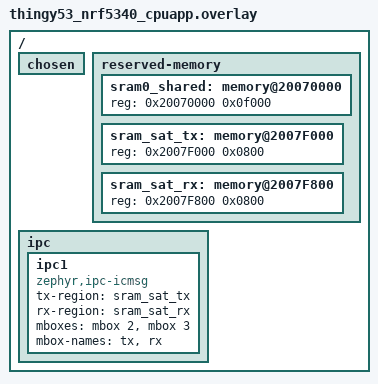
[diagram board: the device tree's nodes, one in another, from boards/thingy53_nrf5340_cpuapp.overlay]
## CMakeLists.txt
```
# Copyright (c) 2024 HubbleNetwork
# SPDX-License-Identifier: Apache-2.0

cmake_minimum_required(VERSION 3.13.1)
find_package(Zephyr REQUIRED HINTS $ENV{ZEPHYR_BASE})

project(app LANGUAGES C)

if (CONFIG_APP_USE_PASS_PREDICTION)
  if("$ENV{HUBBLE_API_TOKEN}" STREQUAL "")
    message(FATAL_ERROR "HUBBLE_API_TOKEN environment variable must be set")
  endif()

  add_custom_command(
    OUTPUT ${CMAKE_CURRENT_SOURCE_DIR}/src/sat_params.c
    COMMAND ${Python3_EXECUTABLE} ${ZEPHYR_HUBBLENETWORK_SDK_MODULE_DIR}/tools/orbital_params_fetch.py
    ${CMAKE_CURRENT_SOURCE_DIR}/src/
    DEPENDS ${ZEPHYR_HUBBLENETWORK_SDK_MODULE_DIR}/tools/orbital_params_fetch.py
    COMMENT "Generate EPP files needed for pass prediction"
  )
  add_custom_target(gen_epp DEPENDS ${CMAKE_CURRENT_SOURCE_DIR}/src/sat_params.c)

  # main.c #includes the generated sat_params.c, so the app target must not be
  # compiled until generation has run.
  add_dependencies(app gen_epp)
endif()

target_sources(app PRIVATE src/ble.c)
target_sources(app PRIVATE src/main.c)
target_sources(app PRIVATE src/nvs.c)
target_sources(app PRIVATE src/sat_board.c)
target_sources(app PRIVATE src/sensor.c)
target_sources(app PRIVATE src/shell.c)
target_sources(app PRIVATE src/button.c)

target_sources_ifdef(CONFIG_APP_BLINK_LED app PRIVATE src/led.c)

target_include_directories(app PRIVATE ${CMAKE_CURRENT_SOURCE_DIR}/common)

include(ExternalProject)
```

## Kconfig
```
# Copyright (c) 2026 HubbleNetwork
# SPDX-License-Identifier: Apache-2.0
#
# This file is the application Kconfig entry point. All application Kconfig
# options can be defined here or included via other application Kconfig files.
# You can browse these options using the west targets menuconfig (terminal) or
# guiconfig (GUI).

menu "Zephyr"
source "Kconfig.zephyr"
endmenu

menu "Hubble Network options"

config HUBBLE_DEVICE_KEY
    string "Cryptography key in base64"
    default ""
    help
	Hubble device's cryptographic key

config HUBBLE_RETRANSMISSION_FREQUENCY
    int "Internval between packet"
    default 4
    help
	Period between packets transmissions in a given window.

config HUBBLE_SAMPLE_ADV_FREQUENCY
    int "Frequency to generate new advertisment in seconds"
    default 28800 # 8 hours
    help
        The maximum time to generate a new advertisement packet.
	It must be less than 24h.

config APP_USE_PASS_PREDICTION
    bool "Use pass prediction instead of timestamps"
    help
        Use Hubble Pass prediction algorithm to determine when
	to transmit to satellite.

config APP_BLINK_LED
    bool "Blink LED during satellite transmission"
    select GPIO
    help
        Blink the LED on top of the device to inform when
	it is transmitting to satellite.

if APP_BLINK_LED

choice
	prompt "LED Color for Satellite transmission"
	default APP_LED_RED
	help
	    Select the led color for during satellite transmission.

config APP_LED_RED
	bool "Use red led"

config APP_LED_GREEN
	bool "Use green led"

config APP_LED_BLUE
	bool "Use blue led"

endchoice

endif # APP_BLINK_LED

endmenu

module = APP
module-str = APP
source "subsys/logging/Kconfig.template.log_config"
```

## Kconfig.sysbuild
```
source "share/sysbuild/Kconfig"

config CPUNET_BOARD
string
	default "thingy53/nrf5340/cpunet" if $(BOARD) = "thingy53"
```

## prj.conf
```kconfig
CONFIG_PRINTK=y

CONFIG_IPC_SERVICE=y
CONFIG_IPC_SERVICE_BACKEND_ICMSG=y
CONFIG_MBOX=y

CONFIG_ASSERT=y
CONFIG_HUBBLE_BLE_NETWORK=y
CONFIG_HUBBLE_SAT_NETWORK=y
# CONFIG_LOG=y

# DEBUG

CONFIG_BT=y
CONFIG_BT_BUF_ACL_TX_COUNT=7
CONFIG_BT_SMP=y
CONFIG_BT_PERIPHERAL=y
CONFIG_SYSTEM_WORKQUEUE_STACK_SIZE=2048

CONFIG_BT_DEVICE_NAME="Hubble Network"

CONFIG_BASE64=y


# Enable MCUmgr and dependencies.
# CONFIG_NET_BUF=y
# CONFIG_ZCBOR=y
# CONFIG_CRC=y
# CONFIG_STREAM_FLASH=y
# CONFIG_FLASH_MAP=y

# Some command handlers require a large stack.
CONFIG_SYSTEM_WORKQUEUE_STACK_SIZE=2304
CONFIG_MAIN_STACK_SIZE=2048

# Enable flash operations.
CONFIG_FLASH=y

# Enable most core commands.
CONFIG_NVS=y
CONFIG_FLASH_PAGE_LAYOUT=y


# Shell - Minimize options
CONFIG_SHELL=y
CONFIG_SHELL_PROMPT_UART="HubbleNetwork:~$ "
CONFIG_DEVICE_SHELL=n
CONFIG_DEVICE_SHELL_INIT_CMD=n
CONFIG_DATE_SHELL=n
CONFIG_DEVMEM_SHELL=n
CONFIG_APP_VERSION_SHELL=n
CONFIG_KERNEL_SHELL=n
CONFIG_SHELL_STATS=n
CONFIG_SHELL_CMDS=n
CONFIG_SHELL_CMDS_RESIZE=n

# Sensor
CONFIG_SENSOR=y
CONFIG_SENSOR_INFO=y

CONFIG_BME680=y

# Banner
CONFIG_BOOT_BANNER_STRING="Hubble Network Thingy53"

# GPIO for button
CONFIG_GPIO=y


# Pass prediction
CONFIG_APP_USE_PASS_PREDICTION=y
```

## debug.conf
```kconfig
# Copyright (c) 2024 HubbleNetwork
# SPDX-License-Identifier: Apache-2.0
#
# compiler
CONFIG_DEBUG_OPTIMIZATIONS=y

# logging
CONFIG_LOG=y
CONFIG_APP_LOG_LEVEL_DBG=y
```

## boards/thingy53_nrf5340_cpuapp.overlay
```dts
/*
 * Copyright (c) 2022 Nordic Semiconductor ASA
 *
 * SPDX-License-Identifier: Apache-2.0
 */

/delete-node/ &sram0_shared;

/ {
	chosen {
		/delete-property/ zephyr,ipc_shm;
	};

	reserved-memory {
		#address-cells = <1>;
		#size-cells = <1>;

		sram0_shared: memory@20070000 {
			/* Last 60 kB of sram0 */
			reg = <0x20070000 0x0f000>;
		};

		sram_sat_tx: memory@2007F000 {
			reg = <0x2007F000 0x0800>;
		};

		sram_sat_rx: memory@2007F800 {
			reg = <0x2007F800 0x0800>;
		};
	};

	ipc {
		ipc1: ipc1 {
			compatible = "zephyr,ipc-icmsg";
			tx-region = <&sram_sat_tx>;
			rx-region = <&sram_sat_rx>;
			mboxes = <&mbox 2>, <&mbox 3>;
			mbox-names = "tx", "rx";
			status = "okay";
		};
	};
};
```

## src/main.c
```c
/*
 * Copyright (c) 2026 HubbleNetwork
 *
 * SPDX-License-Identifier: Apache-2.0
 */
#include <zephyr/kernel.h>
#include <zephyr/bluetooth/bluetooth.h>
#include <zephyr/logging/log.h>
#include <zephyr/sys/util.h>
#include <zephyr/sys/base64.h>
#include <zephyr/sys/byteorder.h>
#include <zephyr/ipc/ipc_service.h>

#include <nrf53_cpunet_mgmt.h>

#include <hubble/hubble.h>

#include <math.h>
#include <stdio.h>
#include <stdlib.h>

#include "app.h"
#include "ble.h"
#include "nvs.h"
#include "sat.h"
#include "shell.h"

/* sat ipc packet */
#include "sat_ipc.h"

#define IPC_TIMEOUT_S 3U

LOG_MODULE_REGISTER(main);

K_SEM_DEFINE(timer_sem, 0, 1);
K_SEM_DEFINE(init_sem, 0, 1);
K_SEM_DEFINE(key_sem, 0, 1);
K_SEM_DEFINE(bound_sem, 0, 1);
K_SEM_DEFINE(sat_sem, 0, 1);

K_MUTEX_DEFINE(radio_mutex);

#ifdef CONFIG_APP_USE_PASS_PREDICTION
#include "sat_params.c"
#endif

static uint8_t _hubble_key[CONFIG_HUBBLE_KEY_SIZE];
static struct ipc_ept ep;
uint64_t utc_time;

/* Set a mark in a shared memory so the cpunet can
 * check which stack (BLE or Satellite) should be used
 * when boot.
 *
 * @_val: 1 for Bluetooth Stack
 *        0 for Satellite Stack
 */
#define _CPUNET_STACK_MARK(_val)                                               \
	do {                                                                   \
		*HUBBLE_SAT_MARK = _val;                                       \
		__DSB();                                                       \
		__ISB();                                                       \
	} while (0)

static void _ep_recv(const void *data, size_t len, void *priv)
{
	const struct sat_ipc_base *pkt = (const struct sat_ipc_base *)data;

	LOG_DBG("Received IPC data (%d)", len);

	if (pkt->cmd == SAT_CMD_OK) {
		k_sem_give(&sat_sem);
	}
}

int ipc_send(const uint8_t *data, size_t len)
{
	int ret = ipc_service_send(&ep, data, len);

	if (ret < 0) {
		return ret;
	}

	return k_sem_take(&sat_sem, K_SECONDS(IPC_TIMEOUT_S));
}

static void _ep_bound(void *priv)
{
	LOG_DBG("ipc bound");

	k_sem_give(&bound_sem);
}

static struct ipc_ept_cfg ep_cfg = {
	.name = "sat_ipc",
	.cb =
		{
			.bound = _ep_bound,
			.received = _ep_recv,
		},
};

const struct device *sat_ipc;

static int _sat_enable(void)
{
	int err;
	struct sat_ipc_base pkt = {
		.cmd = SAT_CMD_INIT,
	};

	LOG_INF("Run network core");

	_CPUNET_STACK_MARK(0);

	nrf53_cpunet_enable(true);

	sat_ipc = DEVICE_DT_GET(DT_NODELABEL(ipc1));

	err = ipc_service_open_instance(sat_ipc);
	if ((err < 0) && (err != -EALREADY)) {
		LOG_ERR("ipc_service_open_instance() failure");
		return err;
	}

	err = ipc_service_register_endpoint(sat_ipc, &ep, &ep_cfg);
	if (err < 0) {
		LOG_ERR("ipc_service_register_endpoint() failure");
		return err;
	}

	k_sem_take(&bound_sem, K_FOREVER);

	return ipc_send((const uint8_t *)&pkt, sizeof(pkt));
}

static int _sat_disable(void)
{
	int err;

	err = ipc_service_deregister_endpoint(&ep);
	if (err) {
		LOG_ERR("Deregistering HCI endpoint failed with: %d", err);
		return err;
	}

	err = ipc_service_close_instance(sat_ipc);
	if (err != 0) {
		LOG_ERR("Closing ipc service  failed with %d\n", err);
		return err;
	}

	nrf53_cpunet_enable(false);

	return 0;
}

int crypto_key_set(const char *key, size_t len)
{
	int ret;
	size_t olen;

	if (len != (ceil((double)CONFIG_HUBBLE_KEY_SIZE / 3) * 4)) {
		return -EINVAL;
	}

	ret = base64_decode(_hubble_key, sizeof(_hubble_key), &olen, key, len);
	if (ret == 0) {
		(void)hubble_nvs_write(HUBBLE_KEY_ID, _hubble_key,
				       sizeof(_hubble_key));
		k_sem_give(&key_sem);
	}

	return ret;
}

static int _key_get(void)
{
	if (hubble_nvs_read(HUBBLE_KEY_ID, _hubble_key, sizeof(_hubble_key)) ==
	    sizeof(_hubble_key)) {
		return 0;
	}

	return -ENOENT;
}

bool crypto_key_is_set(void)
{
	char _k[CONFIG_HUBBLE_KEY_SIZE] = {0};

	return memcmp(_hubble_key, _k, CONFIG_HUBBLE_KEY_SIZE) != 0;
}

int main(void)
{
	int err;

	if (_key_get() == 0) {
		k_sem_give(&key_sem);
	} else if (strlen(CONFIG_HUBBLE_DEVICE_KEY) != 0) {
		err = crypto_key_set(CONFIG_HUBBLE_DEVICE_KEY,
				     strlen(CONFIG_HUBBLE_DEVICE_KEY));
		if (err != 0) {
			LOG_ERR("Invalid key provided!");
		}
	}

	_CPUNET_STACK_MARK(1);

	err = bt_enable(NULL);
	if (err != 0) {
		LOG_ERR("Bluetooth init failed (err %d)", err);
		return err;
	}

	err = ble_init();
	if (err != 0) {
		goto end;
	}

	/* We sit here waiting to have UTC and KEY */
	k_sem_take(&init_sem, K_FOREVER);
	k_sem_take(&key_sem, K_FOREVER);

	/* Initialize utc time. */
	err = hubble_init(utc_time, _hubble_key);
	if (err != 0) {
		LOG_ERR("Failed to initialize Hubble BLE Network");
		return err;
	}

#ifdef CONFIG_APP_USE_PASS_PREDICTION
	err = hubble_sat_satellites_set(sats, ARRAY_SIZE(sats));
	if (err != 0) {
		LOG_ERR("Failed to set Hubble Sats");
		return err;
	}
#endif

	while (true) {
		(void)sat_schedule_next_transmission();
		/**
		 * Here we are assuming that we are going to transmit to
		 * satellite at least once a day, otherwise we will not be able
		 * to synchronize with the BLE network.
		 */
		ble_enable(false);

		/* After that we will be transmitting to satellite */
		k_sem_take(&timer_sem, K_FOREVER);

		ble_disable(false);

		k_mutex_lock(&radio_mutex, K_FOREVER);
		err = _sat_enable();
		if (err < 0) {
			LOG_ERR("Failed to enable satellite IPC: %d", err);
			goto sat_cleanup;
		}

		err = sat_transmit();
		if (err < 0) {
			LOG_WRN("Failed to transmit packet");
		}

sat_cleanup:
		_sat_disable();
		k_mutex_unlock(&radio_mutex);
		_CPUNET_STACK_MARK(1);
	}
end:
	bt_disable();

	return err;
}
```

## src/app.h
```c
/*
 * Copyright (c) 2026 HubbleNetwork
 *
 * SPDX-License-Identifier: Apache-2.0
 */

/**
 * @file app.h
 * @brief Application-level interface for SAT transmission and sensor access.
 *
 * Provides functions to configure and trigger SAT transmissions, send raw IPC
 * messages, and read sensor data from the board.
 */

#ifndef APP_H
#define APP_H

#include <inttypes.h>
#include <stdlib.h>

#include <zephyr/drivers/sensor.h>


extern struct k_mutex radio_mutex;

/**
 * @brief Payload type for a SAT transmission.
 *
 * Selects the kind of data embedded in the SAT packet. Sensor-backed values
 * map directly to the corresponding Zephyr @c sensor_channel so the correct
 * channel is sampled automatically.
 */
enum sat_payload_type {
	CUSTOM, /**< Arbitrary caller-supplied bytes. */
	GAUGE_VOLTAGE = SENSOR_CHAN_GAUGE_VOLTAGE, /**< Battery gauge voltage. */
	TEMP = SENSOR_CHAN_AMBIENT_TEMP,           /**< Ambient temperature. */
	PRESSURE = SENSOR_CHAN_PRESS,              /**< Atmospheric pressure. */
	HUMIDITY = SENSOR_CHAN_HUMIDITY,           /**< Relative humidity. */
	INVALID, /**< Sentinel / error value. */
};

/**
 * @brief Send raw bytes over the inter-processor IPC channel.
 *
 * @param data Pointer to the data buffer to send.
 * @param len  Number of bytes to send.
 * @return 0 on success, negative errno on failure.
 */
int ipc_send(const uint8_t *data, size_t len);

/**
 * @brief Read a sensor value from the board.
 *
 * @param[out] data    Pointer to a @c sensor_value struct that receives the
 *                     measurement.
 * @param      channel Zephyr sensor channel to sample.
 * @return 0 on success, negative errno on failure.
 */
int sensor_data_get(struct sensor_value *data, enum sensor_channel channel);


/**
 * @brief Set the cryptographic key used for SAT payload encryption.
 *
 * @param key Pointer to the key material.
 * @param len Length of the key in bytes.
 * @return 0 on success, negative errno on failure.
 */
int crypto_key_set(const char *key, size_t len);

/**
 * @brief Check whether a cryptographic key has been configured.
 *
 * @return true if a key has been set, false otherwise.
 */
bool crypto_key_is_set(void);

/**
 * @brief Set the device's geographic location for satellite pass prediction.
 *
 * The coordinates are used to compute upcoming satellite passes. This is a
 * no-op unless @c CONFIG_APP_USE_PASS_PREDICTION is enabled.
 *
 * @param lat Latitude in decimal degrees (WGS-84), positive north.
 * @param lon Longitude in decimal degrees (WGS-84), positive east.
 */
void device_location_set(double lat, double lon);

#endif /* APP_H */
```

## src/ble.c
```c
/*
 * Copyright (c) 2026 HubbleNetwork
 *
 * SPDX-License-Identifier: Apache-2.0
 */
#include <zephyr/sys/util.h>
#include <zephyr/sys/byteorder.h>
#include <zephyr/sys/reboot.h>

#include <zephyr/logging/log.h>

#include <zephyr/bluetooth/bluetooth.h>
#include <zephyr/bluetooth/hci.h>
#include <zephyr/bluetooth/hci_vs.h>
#include <zephyr/bluetooth/conn.h>
#include <zephyr/bluetooth/uuid.h>
#include <zephyr/bluetooth/gatt.h>

#include <hubble/hubble.h>
#include <hubble/ble.h>

#include "app.h"
#include "ble.h"
#include "sat.h"

LOG_MODULE_REGISTER(ble);

#define HUBBLE_BLE_UUID_CONNECTABLE 0xFCA7
#define HUBBLE_BLE_BUFFER_LEN       31

#define SPBLE_PKT_CMD               0x02
#define SPBLE_CMD_SETUTC            0x02
#define SPBLE_CMD_SETEPHEMERIS      0x07
#define SPBLE_CMD_SETLOCATION       0x09

#define SVC_UUID                                                               \
	BT_UUID_128_ENCODE(0xef2dc9a1, 0x40be, 0x44b6, 0x9dda, 0x8a00fcd61dc0)
#define CHR_UUID                                                               \
	BT_UUID_128_ENCODE(0xef2dc9a1, 0x40be, 0x44b6, 0x9dda, 0x8a00fcd61dc1)

static bool ble_off_by_user;

static const struct bt_uuid_128 svc_uuid = BT_UUID_INIT_128(SVC_UUID);
static const struct bt_uuid_128 chr_uuid = BT_UUID_INIT_128(CHR_UUID);

static const struct bt_data sd[] = {
	BT_DATA(BT_DATA_NAME_COMPLETE, CONFIG_BT_DEVICE_NAME,
		sizeof(CONFIG_BT_DEVICE_NAME) - 1),
};

static struct bt_data app_ad[] = {
	BT_DATA_BYTES(BT_DATA_UUID16_ALL,
		      BT_UUID_16_ENCODE(HUBBLE_BLE_UUID_CONNECTABLE)),
	BT_DATA_BYTES(BT_DATA_SVC_DATA16,
		      BT_UUID_16_ENCODE(HUBBLE_BLE_UUID_CONNECTABLE)),
};
static uint8_t app_ad_buffer[HUBBLE_BLE_BUFFER_LEN];

extern struct k_sem init_sem;
extern uint64_t utc_time;

int ble_init(void);

static void _ble_work_handler(struct k_work *work)
{
	ble_adv_stop();

	ble_adv_start();
}

K_WORK_DEFINE(_ble_work, _ble_work_handler);

static void _timer_ble_cb(struct k_timer *timer)
{
	k_work_submit(&_ble_work);
}

K_TIMER_DEFINE(ble_timer, _timer_ble_cb, NULL);

static void _adv_provisioning_work_handler(struct k_work *work)
{
	(void)ble_init();
}

K_WORK_DEFINE(_provisioning_work, _adv_provisioning_work_handler);

int ble_adv_start(void)
{
	int err;
	size_t out_len;

	k_timer_start(&ble_timer, K_SECONDS(CONFIG_HUBBLE_SAMPLE_ADV_FREQUENCY),
		      K_NO_WAIT);

	out_len = ARRAY_SIZE(app_ad_buffer);
	err = hubble_ble_advertise_get(NULL, 0, app_ad_buffer, &out_len);
	if (err != 0) {
		return err;
	}

	app_ad[0] = (struct bt_data)BT_DATA_BYTES(
		BT_DATA_UUID16_ALL, BT_UUID_16_ENCODE(HUBBLE_BLE_UUID));
	app_ad[1].data_len = out_len;
	app_ad[1].type = BT_DATA_SVC_DATA16;
	app_ad[1].data = app_ad_buffer;

	return bt_le_adv_start(
		BT_LE_ADV_PARAM(BT_LE_ADV_OPT_USE_NRPA, BT_GAP_ADV_SLOW_INT_MIN,
				BT_GAP_ADV_SLOW_INT_MAX, NULL),
		app_ad, ARRAY_SIZE(app_ad), NULL, 0);
}

void ble_adv_stop(void)
{
	bt_le_adv_stop();
	k_timer_stop(&ble_timer);
}

static void _connected_cb(struct bt_conn *conn, uint8_t err)
{
	k_timer_stop(&ble_timer);
}

static void _disconnected_cb(struct bt_conn *conn, uint8_t reason)
{
	if (utc_time != 0) {
		k_sem_give(&init_sem);
	} else {
		k_work_submit(&_provisioning_work);
	}
}

BT_CONN_CB_DEFINE(conn_callbacks) = {
	.connected = _connected_cb,
	.disconnected = _disconnected_cb,
};

int ble_init(void)
{
	return bt_le_adv_start(
		BT_LE_ADV_PARAM(BT_LE_ADV_OPT_USE_NRPA | BT_LE_ADV_OPT_CONN,
				BT_GAP_ADV_FAST_INT_MIN_2,
				BT_GAP_ADV_FAST_INT_MAX_2, NULL),
		app_ad, 2, sd, ARRAY_SIZE(sd));
}

static ssize_t _chr_write_cb(struct bt_conn *conn,
			     const struct bt_gatt_attr *attr, const void *data,
			     uint16_t len, uint16_t offset, uint8_t flags)
{
	uint8_t *req = (uint8_t *)data;

	if (flags & BT_GATT_WRITE_FLAG_PREPARE) {
		return 0;
	}

	if (req[0] == SPBLE_PKT_CMD) {
		uint8_t cmd = req[1];

		switch (cmd) {
		case SPBLE_CMD_SETUTC:
			if (len != 10) {
				return BT_GATT_ERR(
					BT_ATT_ERR_INVALID_ATTRIBUTE_LEN);
			} else {
				memcpy(&utc_time, req + 2, sizeof(utc_time));
				hubble_time_set(utc_time);
				utc_time = utc_time - k_uptime_get();
			}
			break;
		case SPBLE_CMD_SETEPHEMERIS:
#ifndef CONFIG_APP_USE_PASS_PREDICTION
			if (len > 2 + sizeof(uint32_t)) {
				uint32_t count = 0;
				size_t entry_size =
					sizeof(uint32_t) + sizeof(uint16_t);
				uint8_t *p = (req + 2) + sizeof(uint32_t);
				size_t available = len - 2 - sizeof(uint32_t);

				memcpy(&count, (req + 2), sizeof(count));

				for (uint32_t i = 0; i < count; i++) {
					if (available < entry_size) {
						break;
					}

					int resp = sat_pass_add(
						*(uint32_t *)p,
						*(uint16_t *)(p +
							      sizeof(uint32_t)));
					if (resp != 0) {
						break;
					}

					p += entry_size;
					available -= entry_size;
				}
			}
#endif /* CONFIG_APP_USE_PASS_PREDICTION */
			break;
		case SPBLE_CMD_SETLOCATION:
#ifdef CONFIG_APP_USE_PASS_PREDICTION
			if (len != 2 + 2 * sizeof(double)) {
				return BT_GATT_ERR(
					BT_ATT_ERR_INVALID_ATTRIBUTE_LEN);
			} else {
				double lat, lon;
				memcpy(&lat, (req + 2), sizeof(double));
				memcpy(&lon, (req + 2) + sizeof(double),
				       sizeof(double));

				device_location_set(lat, lon);
			}
#endif /* CONFIG_APP_USE_PASS_PREDICTION */
			break;
		default:
			break;
		}
	}

	return len;
}

void ble_enable(bool user_requested)
{
	int err;

	k_mutex_lock(&radio_mutex, K_FOREVER);

	if (!user_requested && ble_off_by_user) {
		goto end;
	}

	if (user_requested) {
		ble_off_by_user = false;
	}

	err = bt_enable(NULL);
	if (err != 0 && err != -EALREADY) {
		LOG_ERR("Bluetooth init failed (err %d)", err);
		goto end;
	}

	/* Time is not synced */
	if (utc_time == 0) {
		err = ble_init();
		if (err < 0) {
			LOG_ERR("Failed to advertise time sync: %d", err);
		}
	} else {
		err = ble_adv_start();
		if (err < 0) {
			LOG_ERR("Failed to get the advertisement data: %d", err);
		}
	}

end:
	k_mutex_unlock(&radio_mutex);
}

void ble_disable(bool user_requested)
{
	k_mutex_lock(&radio_mutex, K_FOREVER);

	if (user_requested) {
		ble_off_by_user = true;
	}

	/* Stop the timer and disable BLE */
	ble_adv_stop();
	bt_disable();

	k_mutex_unlock(&radio_mutex);
}

/* Check for BT_GATT_PERM_WRITE_LESC permissions */
BT_GATT_SERVICE_DEFINE(
	vnd_svc, BT_GATT_PRIMARY_SERVICE(&svc_uuid),
	BT_GATT_CHARACTERISTIC(&chr_uuid.uuid,
			       BT_GATT_CHRC_WRITE | BT_GATT_CHRC_NOTIFY |
				       BT_GATT_CHRC_WRITE_WITHOUT_RESP |
				       BT_GATT_CHRC_EXT_PROP,
			       BT_GATT_PERM_WRITE | BT_GATT_PERM_PREPARE_WRITE,
			       NULL, _chr_write_cb, NULL), );
```

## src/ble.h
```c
/*
 * Copyright (c) 2025 HubbleNetwork
 *
 * SPDX-License-Identifier: Apache-2.0
 */

/**
 * @file ble.h
 * @brief Bluetooth LE advertising interface.
 *
 * Provides functions to initialise the BLE stack, control advertising, and
 * query timing information used to synchronise SAT transmissions with BLE
 * advertisement slots.
 */

#ifndef BLE_H
#define BLE_H

#include <zephyr/bluetooth/uuid.h>

/**
 * @brief Initialise the Bluetooth LE subsystem.
 *
 * Registers GATT services, sets up the advertising data, and prepares the
 * controller for use. Must be called once before any other BLE function.
 *
 * @return 0 on success, negative errno on failure.
 */
int ble_init(void);

/**
 * @brief Start Bluetooth LE advertising.
 *
 * Begins broadcasting advertisement packets. @ref ble_init must have been
 * called successfully before invoking this function.
 *
 * @return 0 on success, negative errno on failure.
 */
int ble_adv_start(void);

/**
 * @brief Stop Bluetooth LE advertising.
 *
 * Halts advertisement broadcasting. Safe to call even if advertising is
 * already stopped.
 */
void ble_adv_stop(void);

void ble_enable(bool user_requested);

void ble_disable(bool user_requested);

#endif /* BLE_H */
```

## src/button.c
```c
/*
 * Copyright (c) 2026 HubbleNetwork
 *
 * SPDX-License-Identifier: Apache-2.0
 */

#include <inttypes.h>
#include <zephyr/bluetooth/bluetooth.h>
#include <zephyr/device.h>
#include <zephyr/drivers/gpio.h>
#include <zephyr/kernel.h>

#include "ble.h"

#define SW0_NODE DT_ALIAS(sw0)
#if !DT_NODE_HAS_STATUS_OKAY(SW0_NODE)
#error "Unsupported board: sw0 devicetree alias is not defined"
#endif

static const struct gpio_dt_spec _button =
	GPIO_DT_SPEC_GET_OR(SW0_NODE, gpios, {0});
static struct gpio_callback _button_cb_data;
static struct k_work _button_work;

static void _button_pressed_worker(struct k_work *work)
{
	if (!bt_is_ready()) {
		ble_enable(true);
	} else {
		ble_disable(true);
	}
}

static void _button_pressed(const struct device *dev, struct gpio_callback *cb,
			    uint32_t pins)
{
	/* We are in ISR so let's delegate the task to a work queue. */
	k_work_submit(&_button_work);
}

int _button_init(void)
{
	int ret = 0;

	if (!gpio_is_ready_dt(&_button)) {
		return -1;
	}

	ret = gpio_pin_configure_dt(&_button, GPIO_INPUT);
	if (ret != 0) {
		return ret;
	}

	ret = gpio_pin_interrupt_configure_dt(&_button, GPIO_INT_EDGE_TO_ACTIVE);
	if (ret != 0) {
		return ret;
	}

	gpio_init_callback(&_button_cb_data, _button_pressed, BIT(_button.pin));
	gpio_add_callback(_button.port, &_button_cb_data);

	k_work_init(&_button_work, _button_pressed_worker);

	return ret;
}

SYS_INIT(_button_init, APPLICATION, CONFIG_APPLICATION_INIT_PRIORITY);
```

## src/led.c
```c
/*
 * Copyright (c) 2026 HubbleNetwork
 *
 * SPDX-License-Identifier: Apache-2.0
 */

#include <zephyr/kernel.h>
#include <zephyr/drivers/gpio.h>

#define LED_INTERVAL_S   1

#if defined(CONFIG_APP_LED_GREEN)
#define LED_NODE DT_ALIAS(led1)
#elif defined(CONFIG_APP_LED_BLUE)
#define LED_NODE DT_ALIAS(led2)
#else
#define LED_NODE DT_ALIAS(led0)
#endif

static const struct gpio_dt_spec led = GPIO_DT_SPEC_GET(LED_NODE, gpios);

static void led_blink_cb(struct k_timer *timer)
{
	(void)gpio_pin_toggle_dt(&led);
}

static void led_stop_cb(struct k_timer *timer)
{
	(void)gpio_pin_configure_dt(&led, GPIO_OUTPUT_INACTIVE);
}

K_TIMER_DEFINE(led_timer, led_blink_cb, led_stop_cb);

int led_blink_start(void)
{
	int ret;

	if (!gpio_is_ready_dt(&led)) {
		return -EAGAIN;
	}

	ret = gpio_pin_configure_dt(&led, GPIO_OUTPUT_ACTIVE);
	if (ret < 0) {
		return ret;
	}

	k_timer_start(&led_timer, K_SECONDS(LED_INTERVAL_S), K_SECONDS(LED_INTERVAL_S));

	return 0;
}

void led_blink_stop(void)
{
	k_timer_stop(&led_timer);
}
```

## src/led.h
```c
/*
 * Copyright (c) 2026 HubbleNetwork
 *
 * SPDX-License-Identifier: Apache-2.0
 */

#ifndef LED_H
#define LED_H

#ifdef CONFIG_APP_BLINK_LED

/**
 * @brief Start blinking the LED
 *
 * Start blinking the LED. The LED selection depends on Kconfig: led1 for
 * CONFIG_APP_LED_GREEN, led2 for CONFIG_APP_LED_BLUE, or led0 otherwise.
 *
 * @retval 0 on success.
 * @retval -EAGAIN if the device is not ready.
 * @retval negative errno on GPIO configuration failure.
 */
int led_blink_start(void);

/**
 * @brief Stop blinking the LED and turn it off.
 *
 * Stops blinking the LED.
 */
void led_blink_stop(void);

#else

static inline int led_blink_start(void)
{
	return 0;
}

static inline void led_blink_stop(void)
{
}

#endif	/* CONFIG_APP_BLINK_LED */

#endif 	/* LED_H  */
```

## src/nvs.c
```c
/*
 * Copyright (c) 2025 HubbleNetwork
 *
 * SPDX-License-Identifier: Apache-2.0
 */

#include <zephyr/drivers/flash.h>
#include <zephyr/storage/flash_map.h>
#include <zephyr/kvss/nvs.h>

#include "nvs.h"


#define NVS_PARTITION        storage_partition
#define NVS_PARTITION_DEVICE PARTITION_DEVICE(NVS_PARTITION)
#define NVS_PARTITION_OFFSET PARTITION_OFFSET(NVS_PARTITION)
#define NVS_PARTITION_SIZE   PARTITION_SIZE(NVS_PARTITION)

#define KEY_ID               1

static struct nvs_fs fs;

int _nvs_init(void)
{
	int err;
	struct flash_pages_info info;

	fs.flash_device = NVS_PARTITION_DEVICE;
	if (!device_is_ready(fs.flash_device)) {
		return -1;
	}

	fs.offset = NVS_PARTITION_OFFSET;
	err = flash_get_page_info_by_offs(fs.flash_device, fs.offset, &info);
	if (err != 0) {
		return -1;
	}

	fs.sector_size = info.size;
	fs.sector_count = NVS_PARTITION_SIZE / fs.sector_size;

	err = nvs_mount(&fs);
	if (err != 0) {
		;
		return -1;
	}

	return 0;
}

int hubble_nvs_read(enum hubble_nvs_id id, uint8_t *data, size_t len)
{
	return nvs_read(&fs, id, data, len);
}

int hubble_nvs_write(enum hubble_nvs_id id, const uint8_t *data, size_t len)
{
	(void)nvs_delete(&fs, id);
	return nvs_write(&fs, id, data, len);
}

/* Just using a priority lower than FLASH_INIT_PRIORITY */
SYS_INIT(_nvs_init, APPLICATION, CONFIG_APPLICATION_INIT_PRIORITY);
```

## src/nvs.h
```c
/*
 * Copyright (c) 2025 HubbleNetwork
 *
 * SPDX-License-Identifier: Apache-2.0
 */

/**
 * @file nvs.h
 * @brief Non-volatile storage (NVS) interface for Hubble persistent data.
 *
 * Provides typed read/write access to NVS entries identified by
 * @ref hubble_nvs_id values.
 */

#ifndef NVS_H
#define NVS_H

#include <inttypes.h>

/**
 * @brief Identifiers for Hubble NVS entries.
 */
enum hubble_nvs_id {
	HUBBLE_KEY_ID, /**< Hubble device key. */
};

/**
 * @brief Read data from non-volatile storage (NVS).
 *
 * This function reads data associated with a specific ID from NVS into
 * the provided buffer.
 *
 * @param id   The identifier for the data to be read.
 * @param data Pointer to the buffer where the read data will be stored.
 *             The buffer must be pre-allocated by the caller.
 * @param len  The length of the data to be read, in bytes.
 *             This ensures that the function does not read beyond the
 *             allocated buffer size.
 *
 * @return 0 on success, or a negative value on error.
 *         Possible errors include:
 *         - Invalid ID
 *         - Insufficient buffer size
 *         - Read failure
 */
int hubble_nvs_read(enum hubble_nvs_id id, uint8_t *data, size_t len);

/**
 * @brief Write data to non-volatile storage (NVS).
 *
 * This function writes data to NVS, associating it with a specific ID.
 *
 * @param id   The identifier for the data to be written.
 * @param data Pointer to the buffer containing the data to be written.
 * @param len  The length of the data to be written, in bytes.
 *
 * @return 0 on success, or a negative value on error.
 *         Possible errors include:
 *         - Invalid ID
 *         - Write failure
 *         - Insufficient storage space
 */
int hubble_nvs_write(enum hubble_nvs_id id, const uint8_t *data, size_t len);

#endif /* NVS_H */
```

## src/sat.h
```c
/*
 * Copyright (c) 2026 HubbleNetwork
 *
 * SPDX-License-Identifier: Apache-2.0
 */

/**
 * @file sat.h
 * @brief SAT transmission control interface.
 *
 * Provides functions to configure and drive SAT transmissions: scheduling
 * the next window, tuning RF power and retransmission cadence, setting the
 * payload, and triggering the actual over-the-air burst.
 *
 * Typical call sequence:
 *   1. sat_pass_add() — populate the transmission schedule
 *      from satellite pass data received over BLE.
 *   2. sat_payload_set()             — choose what data to embed in each packet.
 *   3. sat_schedule_next_transmission() — arm the kernel timer for the next window.
 *   4. sat_transmit()                — called from the timer callback to send.
 */

#ifndef SAT_H
#define SAT_H

/**
 * @brief Arm the kernel timer for the next scheduled transmission window.
 *
 * Walks the pre-loaded timestamp table (populated via
 * sat_pass_add()) to find the earliest future satellite pass,
 * then starts a one-shot timer that fires when that window opens.
 *
 * @return 0 on success, -1 when no future window is available.
 */
int sat_schedule_next_transmission(void);

/**
 * @brief Set the SAT retransmission interval.
 *
 * Within a single transmission window the packet is sent repeatedly at this
 * cadence until the window closes.
 *
 * @param retransmission_s Interval between retransmissions, in seconds.
 * @return 0 on success, negative errno on failure.
 */
int sat_retransmission_set(uint8_t retransmission_s);

/**
 * @brief Set the SAT transmit power.
 *
 * @param power Transmit power level in dBm.
 * @return 0 on success, negative errno on failure.
 */
int sat_power_set(int8_t power);

/**
 * @brief Set the payload for the next SAT transmission.
 *
 * For sensor-backed types (TEMP, PRESSURE, HUMIDITY, GAUGE_VOLTAGE) @p data
 * may be NULL and @p len zero — the driver is sampled automatically at
 * transmit time. For CUSTOM, @p data and @p len must describe the raw bytes
 * to embed.
 *
 * @param type Payload type; see @ref sat_payload_type.
 * @param data Pointer to payload bytes, or NULL for sensor-backed types.
 * @param len  Length of @p data in bytes, or 0 for sensor-backed types.
 * @return 0 on success, negative errno on failure.
 */
int sat_payload_set(enum sat_payload_type type, const uint8_t *data, size_t len);

/**
 * @brief Register a satellite pass window with the scheduler.
 *
 * Each call appends one entry to the internal timestamp table.  The table
 * holds up to 300 entries; calls beyond that return -ENOSPC.  Entries are
 * consumed in order by sat_schedule_next_transmission().
 *
 * @param timestamp UTC epoch second at which the pass window opens.
 * @param duration  Length of the pass window in seconds.
 * @return 0 on success, -ENOSPC when the table is full.
 */
int sat_pass_add(uint32_t timestamp, uint16_t duration);

/**
 * @brief Trigger a SAT transmission with the currently configured payload.
 *
 * Builds a Hubble SAT packet from the active payload, then retransmits it
 * repeatedly (at the configured interval) for the duration of the current
 * pass window.  Blocks until the window closes.
 *
 * @return 0 on success, negative errno on failure.
 */
int sat_transmit(void);

/**
 * @brief Query whether a SAT transmission is currently in progress.
 *
 * @return true while sat_transmit() is executing, false otherwise.
 */
bool sat_is_transmitting(void);

/**
 * @brief Get the next scheduled transmission window.
 *
 * Only available when pass prediction (CONFIG_APP_USE_PASS_PREDICTION) is
 * enabled. Returns the start time of the pass most recently armed by
 * sat_schedule_next_transmission().
 *
 * @param timestamps Buffer filled with upcoming pass start times, as Unix
 *                   time in seconds.
 * @param len        Number of entries @p timestamps can hold.
 * @return Number of timestamps written to @p timestamps (0 or more), or -1
 *         when no window is scheduled.
 */
int sat_next_transmission_get(uint32_t *timestamps, uint16_t len);

#endif
```

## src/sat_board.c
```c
/*
 * Copyright (c) 2026 Hubble Network, Inc.
 *
 * SPDX-License-Identifier: Apache-2.0
 */

#include <errno.h>
#include <stddef.h>

#include <zephyr/logging/log.h>
#include <zephyr/drivers/fuel_gauge.h>
#include <zephyr/ipc/ipc_service.h>
#include <zephyr/kernel.h>

#include <hubble/hubble.h>
#include <hubble/sat.h>

#ifdef CONFIG_APP_USE_PASS_PREDICTION
#include <hubble/sat/pass_prediction.h>
#endif

#include "sat_ipc.h"
#include "app.h"
#include "ble.h"
#include "led.h"
#include "sat.h"

LOG_MODULE_REGISTER(sat);

#define HUBBLE_NUMBER_OF_TIMESTAMPS 300

#define HUBBLE_FOR_WHILE(_period)                                              \
	for (int64_t _now = k_uptime_get(), _end = k_uptime_get() + (_period); \
	     _now <= _end; _now = k_uptime_get())

static int8_t _power = 0; /* Default is 0dbm the max for nrf53. */
static uint8_t _retransmission_frequency_s =
	CONFIG_HUBBLE_RETRANSMISSION_FREQUENCY;

static uint8_t _custom_payload_buffer[HUBBLE_SAT_PAYLOAD_MAX];
static uint8_t _custom_payload_size;
static enum sat_payload_type _payload_type = INVALID;
static bool _transmitting;
extern struct k_sem timer_sem;
extern uint64_t utc_time;


#ifdef CONFIG_APP_USE_PASS_PREDICTION
static struct hubble_sat_pass_info next_pass;
static struct hubble_sat_device_pos device_pos;
#else
static uint16_t sat_passes_idx;
static uint16_t sat_passes_count;
static struct _sat_pass {
	uint32_t timestamp;
	uint16_t duration;
} __packed sat_passes[HUBBLE_NUMBER_OF_TIMESTAMPS] = {0};
#endif /* CONFIG_APP_USE_PASS_PREDICTION */

int sat_retransmission_set(uint8_t retransmission_s)
{
	_retransmission_frequency_s = retransmission_s;

	return 0;
}

int sat_power_set(int8_t power)
{
	_power = power;

	return 0;
}

int sat_payload_set(enum sat_payload_type type, const uint8_t *data, size_t len)
{
	_payload_type = type;

	if (len != 0) {
		memcpy(_custom_payload_buffer, data, len);
		_custom_payload_size = len;
	}

	return 0;
}

int hubble_sat_board_init(void)
{
	/**
	 * Do nothing here since we need to initialize
	 * the board everytime with switch stacks in the
	 * network core
	 */

	return 0;
}

int hubble_sat_board_enable(void)
{
	struct sat_ipc_base pkt = {
		.cmd = SAT_CMD_ENABLE,
	};

	LOG_DBG("sat board enable");

	ipc_send((const uint8_t *)&pkt, sizeof(pkt));

	return 0;
}

int hubble_sat_board_disable(void)
{
	struct sat_ipc_base pkt = {
		.cmd = SAT_CMD_DISABLE,
	};

	LOG_DBG("sat board disable");
	ipc_send((const uint8_t *)&pkt, sizeof(pkt));

	return 0;
}

int hubble_sat_board_packet_send(const struct hubble_sat_packet_frames *packet)
{
	struct sat_ipc_packet pkt = {
		.base =
			{
				.cmd = SAT_CMD_SEND,
			},
	};

	memcpy(&pkt.packet, packet, sizeof(*packet));
	ipc_send((const uint8_t *)&pkt, sizeof(pkt));

	return 0;
}

static uint8_t _channel_to_hubble(int channel)
{
	uint8_t ret = 0;

	switch (channel) {
	case SENSOR_CHAN_AMBIENT_TEMP:
		ret = 1;
		break;
	case SENSOR_CHAN_PRESS:
		ret = 2;
		break;
	case SENSOR_CHAN_HUMIDITY:
		ret = 3;
		break;
	case SENSOR_CHAN_GAUGE_VOLTAGE:
		ret = 4;
		break;
	default:
		break;
	}

	return ret;
}

bool sat_is_transmitting(void)
{
	return _transmitting;
}

#ifndef CONFIG_APP_USE_PASS_PREDICTION
static int sat_transmission_time_get(void)
{
	if (sat_passes_idx >= sat_passes_count) {
		return -1;
	}

	return sat_passes[sat_passes_idx].duration;
}
#endif /* !CONFIG_APP_USE_PASS_PREDICTION */

static size_t _nearest_packet_len_get(size_t pkt_len)
{
	if (pkt_len == 0) {
		return 0U;
	} else if (pkt_len < 4U) {
		return 4U;
	} else if (pkt_len < 9U) {
		return 9U;
	} else if (pkt_len < 13U) {
		return 13U;
	}

	return pkt_len;
}

int sat_transmit(void)
{
	int ret;
	struct hubble_sat_packet pkt;
	uint8_t pkt_buffer[HUBBLE_SAT_PAYLOAD_MAX] = {0};
	size_t pkt_len = 0;

#ifdef CONFIG_FUEL_GAUGE
	struct sensor_value sensor_data;
	const struct device *const dev = DEVICE_DT_GET(DT_NODELABEL(fuel_gauge));

	pkt_buffer[0] = _channel_to_hubble(_payload_type);

	if (_payload_type == CUSTOM) {
		pkt_len = HUBBLE_SAT_PAYLOAD_MAX;
		memcpy(&pkt_buffer[1], _custom_payload_buffer,
		       _custom_payload_size);
	} else {
		if (_payload_type == GAUGE_VOLTAGE) {
			fuel_gauge_prop_t poll_props =
				FUEL_GAUGE_RELATIVE_STATE_OF_CHARGE;
			union fuel_gauge_prop_val poll_val;

			ret = fuel_gauge_get_props(dev, &poll_props, &poll_val,
						   1);
			if (ret == 0) {
				pkt_len =
					sizeof(poll_val.relative_state_of_charge) +
					1;
				memcpy(&pkt_buffer[1],
				       &poll_val.relative_state_of_charge,
				       sizeof(poll_val.relative_state_of_charge));
			}
		} else {
			ret = sensor_data_get(&sensor_data, _payload_type);
			if (ret == 0) {
				pkt_len = sizeof(sensor_data) + 1;
				memcpy(&pkt_buffer[1], &sensor_data,
				       sizeof(sensor_data));
			}
		}
	}
#endif
	pkt_len = _nearest_packet_len_get(pkt_len);

	ret = hubble_sat_packet_get(&pkt, pkt_buffer, pkt_len);
	if (ret != 0) {
		return ret;
	}

	_transmitting = true;
	(void)led_blink_start();

#ifndef CONFIG_APP_USE_PASS_PREDICTION
	HUBBLE_FOR_WHILE(sat_transmission_time_get() * 1000)
	{
		ret = hubble_sat_packet_send(&pkt, HUBBLE_SAT_RELIABILITY_NONE);
		if (ret != 0) {
			return ret;
		}
		k_sleep(K_SECONDS(_retransmission_frequency_s));
	}
#else
	ret = hubble_sat_packet_send(&pkt, HUBBLE_SAT_RELIABILITY_NORMAL);
	if (ret != 0) {
		return ret;
	}
#endif /* !CONFIG_APP_USE_PASS_PREDICTION */

	(void)led_blink_stop();
	_transmitting = false;

	return 0;
}

static void _timer_cb(struct k_timer *timer)
{
	k_sem_give(&timer_sem);
}

K_TIMER_DEFINE(sat_timer, _timer_cb, NULL);

int sat_pass_add(uint32_t timestamp, uint16_t duration)
{
#ifndef CONFIG_APP_USE_PASS_PREDICTION
	if (sat_passes_count >= HUBBLE_NUMBER_OF_TIMESTAMPS) {
		return -ENOSPC;
	}

	sat_passes[sat_passes_count].timestamp = timestamp;
	sat_passes[sat_passes_count].duration = duration;

	sat_passes_count++;
#endif

	return 0;
}

int sat_schedule_next_transmission(void)
{
	uint32_t timeout;
	uint64_t now_ms = hubble_time_get();

#ifdef CONFIG_APP_USE_PASS_PREDICTION
	uint64_t t = now_ms;

	/* A pass that already started (we are in the middle of it) is
	 * skipped, search again from its end until we find one in the future.
	 */
	do {
		if (hubble_sat_next_pass_get(t, &device_pos, &next_pass) != 0) {
			return -1;
		}
		t = next_pass.start + next_pass.duration;
	} while (next_pass.start <= now_ms);

	timeout = (next_pass.start - now_ms) / MSEC_PER_SEC;
#else
	if (sat_passes_idx >= sat_passes_count) {
		return -1;
	}

	while (sat_passes[sat_passes_idx].timestamp <
	       (now_ms / MSEC_PER_SEC) + 1) {
		sat_passes_idx++;
		if (sat_passes_idx >= sat_passes_count) {
			return -1;
		}
	}

	timeout = sat_passes[sat_passes_idx].timestamp - (now_ms / MSEC_PER_SEC);
#endif /* CONFIG_APP_USE_PASS_PREDICTION */

	k_timer_start(&sat_timer, K_SECONDS(timeout), K_NO_WAIT);

	return 0;
}

int sat_next_transmission_get(uint32_t *timestamps, uint16_t len)
{
#ifdef CONFIG_APP_USE_PASS_PREDICTION
	ARG_UNUSED(len);

	if (next_pass.start == 0) {
		return -1;
	}

	*timestamps = next_pass.start / MSEC_PER_SEC;

	return 1;
#else
	uint16_t number_elements = MIN(len, (sat_passes_count - sat_passes_idx));

	for (uint16_t i = 0; i < number_elements; i++) {
		timestamps[i] = sat_passes[sat_passes_idx + i].timestamp;
	}

	return number_elements;
#endif
}

/* Store the device location used as the observer position for pass prediction.
 * No-op when pass prediction is disabled.
 */
void device_location_set(double lat, double lon)
{
#ifdef CONFIG_APP_USE_PASS_PREDICTION
	device_pos.lat = lat;
	device_pos.lon = lon;
#endif
}
```

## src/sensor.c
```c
/*
 * Copyright (c) 2025 HubbleNetwork
 *
 * SPDX-License-Identifier: Apache-2.0
 */

#include "app.h"

#include <zephyr/kernel.h>
#include <zephyr/device.h>
#include <zephyr/drivers/sensor.h>

int sensor_data_get(struct sensor_value *data, enum sensor_channel channel)
{
	static const struct device *const dev = DEVICE_DT_GET_ANY(bosch_bme680);
	int err = 0;

	if (!device_is_ready(dev)) {
		return -EAGAIN;
	}

	err = sensor_sample_fetch(dev);
	if (err == 0) {
		err = sensor_channel_get(dev, channel, data);
	}

	return err;
}
```

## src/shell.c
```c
/*
 * Copyright (c) 2025 HubbleNetwork
 *
 * SPDX-License-Identifier: Apache-2.0
 */
#include <zephyr/kernel.h>
#include <zephyr/bluetooth/bluetooth.h>
#include <zephyr/drivers/fuel_gauge.h>
#include <zephyr/drivers/sensor.h>
#include <zephyr/shell/shell.h>
#include <stdio.h>
#include <stdlib.h>
#include <time.h>

#include "app.h"
#include "ble.h"
#include "sat.h"

#ifdef CONFIG_APP_USE_PASS_PREDICTION
#define NUMBER_OF_TIMESTAMP_TO_PRINT 1
#else
#define NUMBER_OF_TIMESTAMP_TO_PRINT 4
#endif

K_MUTEX_DEFINE(_mutex);

static int _cmd_retransmission(const struct shell *sh, size_t argc, char **argv)
{
	uint8_t freq;

	if (argc != 2) {
		shell_print(sh, "It requires a value between 0 and 10");
		return -EINVAL;
	}

	freq = strtol(argv[1], NULL, 10);
	if ((freq < 0) || (freq > 10)) {
		shell_print(sh, "It requires a value between 0 and 10");
		return -EINVAL;
	}

	k_mutex_lock(&_mutex, K_FOREVER);
	sat_retransmission_set(freq);
	k_mutex_unlock(&_mutex);

	return 0;
}

static enum sensor_channel _sensor_channel_get(const char *str)
{
	if (strncmp(str, "temperature", sizeof("temperature")) == 0) {
		return SENSOR_CHAN_AMBIENT_TEMP;
	} else if (strncmp(str, "pressure", sizeof("pressure")) == 0) {
		return SENSOR_CHAN_PRESS;
	} else if (strncmp(str, "humidity", sizeof("humidity")) == 0) {
		return SENSOR_CHAN_HUMIDITY;
	} else if (strncmp(str, "battery", sizeof("battery")) == 0) {
		return SENSOR_CHAN_GAUGE_VOLTAGE;
	}

	return SENSOR_CHAN_MAX;
}

static int _cmd_payload(const struct shell *sh, size_t argc, char **argv)
{
	int ret = -EINVAL;

	k_mutex_lock(&_mutex, K_FOREVER);

	if (argc == 2) {
		enum sensor_channel channel = _sensor_channel_get(argv[1]);
		if (channel != SENSOR_CHAN_MAX) {
			ret = 0;
		}
		sat_payload_set(channel, NULL, 0);
	} else if ((argc == 3) &&
		   (memcmp("custom", argv[1], strlen("custom")) == 0)) {
		size_t len = strlen(argv[2]);
		if (len < 13) {
			sat_payload_set(CUSTOM, argv[2], len);
			ret = 0;
		}
	}

	k_mutex_unlock(&_mutex);

	if (ret != 0) {
		shell_print(sh, "Invalid payload %s", argv[1]);
	}

	return 0;
}

static int _cmd_sensor(const struct shell *sh, size_t argc, char **argv)
{
	int ret = -EINVAL;
	struct sensor_value data;
	enum sensor_channel chan;

	if (argc == 2) {
		chan = _sensor_channel_get(argv[1]);

		ret = sensor_data_get(&data, chan);

		if (ret == 0) {
			shell_print(sh, "Sensor %s value %d.%06d", argv[1],
				    data.val1, data.val2);
		} else {
			shell_print(sh, "Error %s - %d", argv[1], ret);
		}
	}

	return ret;
}

static int _cmd_status(const struct shell *sh, size_t argc, char **argv)
{
	extern uint64_t utc_time;
	int ret = 0;
	int len;
	uint32_t timestamps[NUMBER_OF_TIMESTAMP_TO_PRINT];

#ifdef CONFIG_FUEL_GAUGE
	const struct device *const dev = DEVICE_DT_GET(DT_NODELABEL(fuel_gauge));
	fuel_gauge_prop_t poll_props[] = {
		FUEL_GAUGE_RELATIVE_STATE_OF_CHARGE,
		FUEL_GAUGE_VOLTAGE,
	};
	union fuel_gauge_prop_val poll_vals[ARRAY_SIZE(poll_props)];
#endif

	if (utc_time == 0) {
		shell_print(sh, "Waiting for time synchronization");
		goto end;
	}

	if (!crypto_key_is_set()) {
		shell_print(sh, "Waiting for hubble cryptographic key");
		goto end;
	}

	if (bt_is_ready()) {
		shell_print(sh, "Beaconing");
	} else if (sat_is_transmitting()) {
		shell_print(sh, "Transmitting to satellite");
	}

	len = sat_next_transmission_get(timestamps, NUMBER_OF_TIMESTAMP_TO_PRINT);

	if (len > 0) {
		shell_print(sh, "Next scheduled transmissions:");
	}

	for (uint16_t i = 0; i < len; i++) {
		struct tm t;
		time_t ts = (time_t)timestamps[i];

		gmtime_r(&ts, &t);
		shell_print(sh, "\t%02d/%02d/%04d %02d:%02d:%02d UTC (%d)",
			    t.tm_mon + 1, t.tm_mday, t.tm_year + 1900,
			    t.tm_hour, t.tm_min, t.tm_sec, timestamps[i]);
	}

end:
#ifdef CONFIG_FUEL_GAUGE
	ret = fuel_gauge_get_props(dev, poll_props, poll_vals,
				   ARRAY_SIZE(poll_props));

	if (ret == 0) {
		shell_print(sh, "Battery - Charge: %d%%, Voltage: %dmV",
			    poll_vals[0].relative_state_of_charge,
			    poll_vals[1].voltage / 1000);
	}
#endif

	return ret;
}

static int _cmd_key(const struct shell *sh, size_t argc, char **argv)
{
	if (argc != 2) {
		shell_print(sh, "Use: key <base64-hubble-key>");
		return -EINVAL;
	}

	if (crypto_key_set(argv[1], strlen(argv[1])) != 0) {
		shell_print(sh, "Invalid key provided");
		return -EINVAL;
	}

	return 0;
}

static int _cmd_ble(const struct shell *sh, size_t argc, char **argv)
{
	if (argc != 2) {
		shell_print(sh, "Use: bluetooth <disable|enable>");
		return -EINVAL;
	}

	if (strncmp(argv[1], "enable", sizeof("enable")) == 0) {
		ble_enable(true);
	} else if (strncmp(argv[1], "disable", sizeof("disable")) == 0) {
		ble_disable(true);
	} else {
		shell_print(
			sh,
			"Invalid parameter %s. Use: bluetooth <disable|enable>",
			argv[1]);
		return -EINVAL;
	}

	return 0;
}

SHELL_CMD_REGISTER(
	retransmission, NULL,
	"Set retransmission frequency (in seconds). Available options: [0-10]",
	_cmd_retransmission);
SHELL_CMD_REGISTER(
	key, NULL,
	"Set a cryptography key (in base64)",
	_cmd_key);
SHELL_CMD_REGISTER(
	payload, NULL,
	"Set payload to transmit. Available options: temperature, pressure, "
	"humidity, battery or custom (sequence of (up to) 12 chars)",
	_cmd_payload);
SHELL_CMD_REGISTER(
	status, NULL,
	"Read device status (beaconing / transmitting sat / waiting)",
	_cmd_status);
SHELL_CMD_REGISTER(
	sensor,
	NULL, "Read sensor data. Available options: temperature, pressure or humidity",
	_cmd_sensor);
SHELL_CMD_REGISTER(
	bluetooth,
	NULL, "Disable or enable Bluetooth. Available options are enable and disable",
	_cmd_ble);
```
